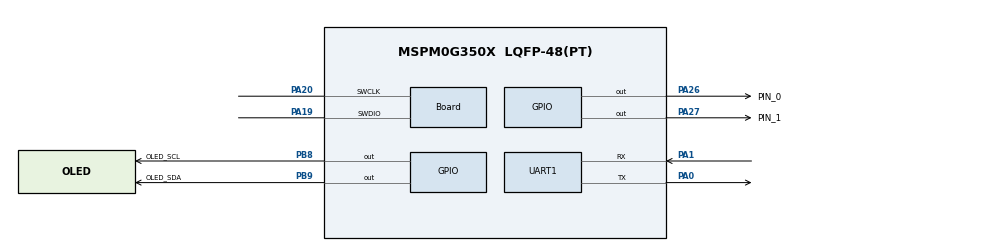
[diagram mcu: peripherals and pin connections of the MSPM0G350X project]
/**
 * @cliArgs --device "MSPM0G350X" --part "Default" --package "LQFP-48(PT)" --product "mspm0_sdk@2.04.00.06"
 * @versions {"tool":"1.23.0+4000"}
 */

/**
 * Import the modules used in this configuration.
 */
const ADC12  = scripting.addModule("/ti/driverlib/ADC12", {}, false);
const ADC121 = ADC12.addInstance();
const Board  = scripting.addModule("/ti/driverlib/Board");
const GPIO   = scripting.addModule("/ti/driverlib/GPIO", {}, false);
const GPIO1  = GPIO.addInstance();
const GPIO2  = GPIO.addInstance();
const SYSCTL = scripting.addModule("/ti/driverlib/SYSCTL");
const TIMER  = scripting.addModule("/ti/driverlib/TIMER", {}, false);
const TIMER1 = TIMER.addInstance();
const UART   = scripting.addModule("/ti/driverlib/UART", {}, false);
const UART1  = UART.addInstance();

/**
 * Write custom configuration values to the imported modules.
 */
ADC121.$name                      = "ADC12_0";
ADC121.sampClkSrc                 = "DL_ADC12_CLOCK_ULPCLK";
ADC121.sampClkDiv                 = "DL_ADC12_CLOCK_DIVIDE_8";
ADC121.adcMem0chansel             = "DL_ADC12_INPUT_CHAN_2";
ADC121.sampleTime0                = "125 us";
ADC121.enabledInterrupts          = ["DL_ADC12_INTERRUPT_MEM0_RESULT_LOADED"];
ADC121.powerDownMode              = "DL_ADC12_POWER_DOWN_MODE_MANUAL";
ADC121.interruptPriority          = "1";
ADC121.peripheral.$assign         = "ADC0";
ADC121.peripheral.adcPin2.$assign = "PA25";
ADC121.adcPin2Config.$name        = "ti_driverlib_gpio_GPIOPinGeneric0";

Board.peripheral.$assign          = "DEBUGSS";
Board.peripheral.swclkPin.$assign = "PA20";
Board.peripheral.swdioPin.$assign = "PA19";

GPIO1.$name                         = "GPIO_GRP_0";
GPIO1.associatedPins.create(2);
GPIO1.associatedPins[0].$name       = "PIN_0";
GPIO1.associatedPins[0].pin.$assign = "PA26";
GPIO1.associatedPins[1].$name       = "PIN_1";
GPIO1.associatedPins[1].pin.$assign = "PA27";

GPIO2.$name                          = "GPIO_OLED";
GPIO2.associatedPins.create(2);
GPIO2.associatedPins[0].$name        = "OLED_SCL";
GPIO2.associatedPins[0].assignedPort = "PORTB";
GPIO2.associatedPins[0].pin.$assign  = "PB8";
GPIO2.associatedPins[1].$name        = "OLED_SDA";
GPIO2.associatedPins[1].assignedPort = "PORTB";
GPIO2.associatedPins[1].pin.$assign  = "PB9";

SYSCTL.forceDefaultClkConfig = true;
SYSCTL.clockTreeEn           = true;

TIMER1.$name              = "TIMER_0";
TIMER1.timerPeriod        = "10 ms";
TIMER1.timerClkPrescale   = 10;
TIMER1.interrupts         = ["LOAD"];
TIMER1.interruptPriority  = "2";
TIMER1.peripheral.$assign = "TIMA0";

UART1.$name                    = "UART_0";
UART1.targetBaudRate           = 115200;
UART1.peripheral.$assign       = "UART0";
UART1.peripheral.rxPin.$assign = "PA1";
UART1.peripheral.txPin.$assign = "PA0";
UART1.txPinConfig.$name        = "ti_driverlib_gpio_GPIOPinGeneric1";
UART1.rxPinConfig.$name        = "ti_driverlib_gpio_GPIOPinGeneric2";

const ProjectConfig              = scripting.addModule("/ti/project_config/ProjectConfig", {}, false);
ProjectConfig.migrationCondition = true;
